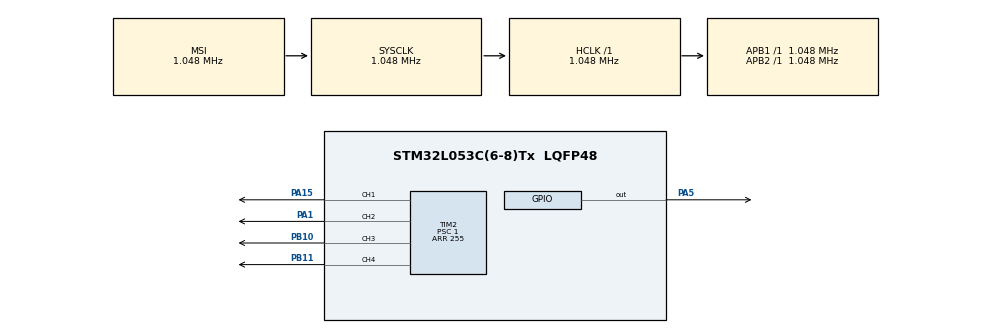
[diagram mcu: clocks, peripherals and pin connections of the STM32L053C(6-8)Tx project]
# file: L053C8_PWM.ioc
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Mcu.Family=STM32L0
Mcu.Name=STM32L053C(6-8)Tx
Mcu.Package=LQFP48
PA1.Signal=S_TIM2_CH2
PA13.Mode=Serial_Wire
PA13.Signal=SYS_SWDIO
PA14.Mode=Serial_Wire
PA14.Signal=SYS_SWCLK
PA15.Signal=S_TIM2_CH1
PA5.Signal=GPIO_Output
PB10.Signal=S_TIM2_CH3
PB11.Signal=S_TIM2_CH4
ProjectManager.HeapSize=0x200
ProjectManager.StackSize=0x400
ProjectManager.TargetToolchain=SW4STM32
RCC.AHBFreq_Value=1048000
RCC.APB1Freq_Value=1048000
RCC.APB1TimFreq_Value=1048000
RCC.APB2Freq_Value=1048000
RCC.APB2TimFreq_Value=1048000
RCC.HCLKFreq_Value=1048000
RCC.HSE_VALUE=8000000
RCC.HSI16_VALUE=16000000
RCC.HSI48_VALUE=48000000
RCC.HSI_VALUE=16000000
RCC.LSE_VALUE=32768
RCC.MSIClockRange=RCC_MSIRANGE_4
RCC.MSI_VALUE=1048000
RCC.SYSCLKFreq_VALUE=1048000
RCC.VCOOutputFreq_Value=48000000
SH.S_TIM2_CH1.0=TIM2_CH1,PWM Generation1 CH1
SH.S_TIM2_CH2.0=TIM2_CH2,PWM Generation2 CH2
SH.S_TIM2_CH3.0=TIM2_CH3,PWM Generation3 CH3
SH.S_TIM2_CH4.0=TIM2_CH4,PWM Generation4 CH4
TIM2.Channel-PWM\ Generation2\ CH2=TIM_CHANNEL_2
TIM2.Channel-PWM\ Generation3\ CH3=TIM_CHANNEL_3
TIM2.Channel-PWM\ Generation4\ CH4=TIM_CHANNEL_4
TIM2.ClockDivision=TIM_CLOCKDIVISION_DIV1
TIM2.OCMode_PWM-PWM\ Generation4\ CH4=TIM_OCMODE_PWM2
TIM2.Period=255
TIM2.Prescaler=1
TIM2.Pulse-PWM\ Generation1\ CH1=127
TIM2.Pulse-PWM\ Generation2\ CH2=64
TIM2.Pulse-PWM\ Generation3\ CH3=64
TIM2.Pulse-PWM\ Generation4\ CH4=127
VP_TIM2_VS_ClockSourceINT.Mode=Internal
board=L053C8_PWM

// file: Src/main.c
/**
  ******************************************************************************
  * File Name          : main.c
  * Description        : Main program body
  ******************************************************************************
  *
  * COPYRIGHT(c) 2017 STMicroelectronics
  *
  * Redistribution and use in source and binary forms, with or without modification,
  * are permitted provided that the following conditions are met:
  *   1. Redistributions of source code must retain the above copyright notice,
  *      this list of conditions and the following disclaimer.
  *   2. Redistributions in binary form must reproduce the above copyright notice,
  *      this list of conditions and the following disclaimer in the documentation
  *      and/or other materials provided with the distribution.
  *   3. Neither the name of STMicroelectronics nor the names of its contributors
  *      may be used to endorse or promote products derived from this software
  *      without specific prior written permission.
  *
  * THIS SOFTWARE IS PROVIDED BY THE COPYRIGHT HOLDERS AND CONTRIBUTORS "AS IS"
  * AND ANY EXPRESS OR IMPLIED WARRANTIES, INCLUDING, BUT NOT LIMITED TO, THE
  * IMPLIED WARRANTIES OF MERCHANTABILITY AND FITNESS FOR A PARTICULAR PURPOSE ARE
  * DISCLAIMED. IN NO EVENT SHALL THE COPYRIGHT HOLDER OR CONTRIBUTORS BE LIABLE
  * FOR ANY DIRECT, INDIRECT, INCIDENTAL, SPECIAL, EXEMPLARY, OR CONSEQUENTIAL
  * DAMAGES (INCLUDING, BUT NOT LIMITED TO, PROCUREMENT OF SUBSTITUTE GOODS OR
  * SERVICES; LOSS OF USE, DATA, OR PROFITS; OR BUSINESS INTERRUPTION) HOWEVER
  * CAUSED AND ON ANY THEORY OF LIABILITY, WHETHER IN CONTRACT, STRICT LIABILITY,
  * OR TORT (INCLUDING NEGLIGENCE OR OTHERWISE) ARISING IN ANY WAY OUT OF THE USE
  * OF THIS SOFTWARE, EVEN IF ADVISED OF THE POSSIBILITY OF SUCH DAMAGE.
  *
  ******************************************************************************
  */
#include "main.h"
#include "stm32l0xx_hal.h"
#include "tim.h"
#include "gpio.h"

/* USER CODE BEGIN PV */
/* Private variables ---------------------------------------------------------*/

/* USER CODE END PV */

void SystemClock_Config(void);
void Error_Handler(void);

/* USER CODE BEGIN PFP */
/* Private function prototypes -----------------------------------------------*/

/* USER CODE END PFP */

int main(void)
{

  /* MCU Configuration----------------------------------------------------------*/

  /* Reset of all peripherals, Initializes the Flash interface and the Systick. */
  HAL_Init();

  /* Configure the system clock */
  SystemClock_Config();

  /* Initialize all configured peripherals */
  MX_GPIO_Init();
  MX_TIM2_Init();

  /* USER CODE BEGIN 2 */
  HAL_TIM_PWM_Start(&htim2, TIM_CHANNEL_1);
    HAL_TIM_PWM_Start(&htim2, TIM_CHANNEL_2);
    HAL_TIM_PWM_Start(&htim2, TIM_CHANNEL_3);
    HAL_TIM_PWM_Start(&htim2, TIM_CHANNEL_4);

  /* USER CODE END 2 */

  /* Infinite loop */
  while (1)
  {

  /* USER CODE BEGIN 3 */
      HAL_GPIO_TogglePin(GPIOA, GPIO_PIN_5);

      /* PB11 */
      HAL_TIM_PWM_Start(&htim2, TIM_CHANNEL_4);
        HAL_Delay(62);
        HAL_TIM_PWM_Stop(&htim2, TIM_CHANNEL_4);
        //HAL_Delay(1000);

        /* PBA15 */
      HAL_TIM_PWM_Start(&htim2, TIM_CHANNEL_1);
        HAL_Delay(62);
        HAL_TIM_PWM_Stop(&htim2, TIM_CHANNEL_1);
        HAL_Delay(100);

  }
  /* USER CODE END 3 */

}

/** System Clock Configuration
*/
void SystemClock_Config(void)
{

  RCC_OscInitTypeDef RCC_OscInitStruct;
  RCC_ClkInitTypeDef RCC_ClkInitStruct;

    /**Configure the main internal regulator output voltage
    */
  __HAL_PWR_VOLTAGESCALING_CONFIG(PWR_REGULATOR_VOLTAGE_SCALE1);

    /**Initializes the CPU, AHB and APB busses clocks
    */
  RCC_OscInitStruct.OscillatorType = RCC_OSCILLATORTYPE_MSI;
  RCC_OscInitStruct.MSIState = RCC_MSI_ON;
  RCC_OscInitStruct.MSICalibrationValue = 0;
  RCC_OscInitStruct.MSIClockRange = RCC_MSIRANGE_4;
  RCC_OscInitStruct.PLL.PLLState = RCC_PLL_NONE;
  if (HAL_RCC_OscConfig(&RCC_OscInitStruct) != HAL_OK)
  {
    Error_Handler();
  }

    /**Initializes the CPU, AHB and APB busses clocks
    */
  RCC_ClkInitStruct.ClockType = RCC_CLOCKTYPE_HCLK|RCC_CLOCKTYPE_SYSCLK
                              |RCC_CLOCKTYPE_PCLK1|RCC_CLOCKTYPE_PCLK2;
  RCC_ClkInitStruct.SYSCLKSource = RCC_SYSCLKSOURCE_MSI;
  RCC_ClkInitStruct.AHBCLKDivider = RCC_SYSCLK_DIV1;
  RCC_ClkInitStruct.APB1CLKDivider = RCC_HCLK_DIV1;
  RCC_ClkInitStruct.APB2CLKDivider = RCC_HCLK_DIV1;

  if (HAL_RCC_ClockConfig(&RCC_ClkInitStruct, FLASH_LATENCY_0) != HAL_OK)
  {
    Error_Handler();
  }

    /**Configure the Systick interrupt time
    */
  HAL_SYSTICK_Config(HAL_RCC_GetHCLKFreq()/1000);

    /**Configure the Systick
    */
  HAL_SYSTICK_CLKSourceConfig(SYSTICK_CLKSOURCE_HCLK);

  /* SysTick_IRQn interrupt configuration */
  HAL_NVIC_SetPriority(SysTick_IRQn, 0, 0);
}

void Error_Handler(void)
{
  while(1)
  {
  }
}

/************************ (C) COPYRIGHT STMicroelectronics *****END OF FILE****/
